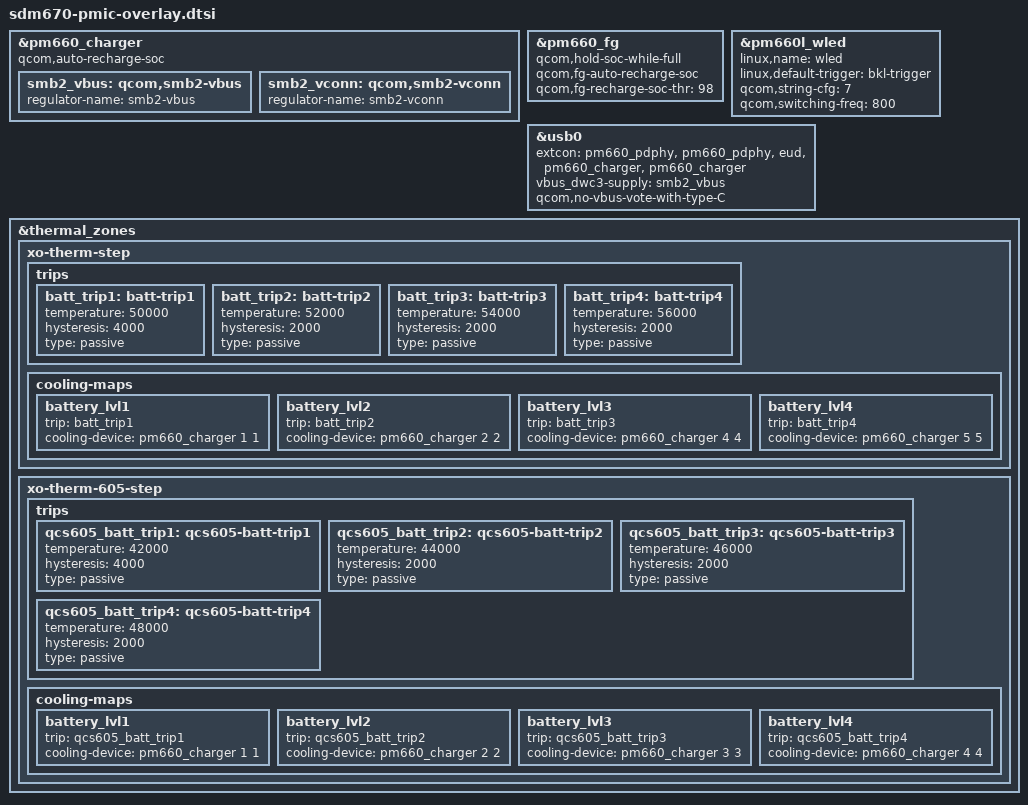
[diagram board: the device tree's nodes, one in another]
/* Copyright (c) 2017-2019, The Linux Foundation. All rights reserved.
 *
 * This program is free software; you can redistribute it and/or modify
 * it under the terms of the GNU General Public License version 2 and
 * only version 2 as published by the Free Software Foundation.
 *
 * This program is distributed in the hope that it will be useful,
 * but WITHOUT ANY WARRANTY; without even the implied warranty of
 * MERCHANTABILITY or FITNESS FOR A PARTICULAR PURPOSE.  See the
 * GNU General Public License for more details.
 */

#include <dt-bindings/interrupt-controller/arm-gic.h>

&pm660_charger {
	#cooling-cells = <2>;
	qcom,auto-recharge-soc;

	smb2_vbus: qcom,smb2-vbus {
		regulator-name = "smb2-vbus";
	};

	smb2_vconn: qcom,smb2-vconn {
		regulator-name = "smb2-vconn";
	};
};

&pm660_fg {
	qcom,hold-soc-while-full;
	qcom,fg-auto-recharge-soc;
	qcom,fg-recharge-soc-thr = <98>;
};

&pm660l_wled {
	linux,name = "wled";
	linux,default-trigger = "bkl-trigger";
	qcom,string-cfg = <7>;
	qcom,switching-freq = <800>;
};

&usb0 {
	extcon = <&pm660_pdphy>, <&pm660_pdphy>, <&eud>,
					<&pm660_charger>, <&pm660_charger>;
	vbus_dwc3-supply = <&smb2_vbus>;
	qcom,no-vbus-vote-with-type-C;
};

&thermal_zones {
	xo-therm-step {
		trips {
			batt_trip1: batt-trip1 {
				temperature = <50000>;
				hysteresis = <4000>;
				type = "passive";
			};
			batt_trip2: batt-trip2 {
				temperature = <52000>;
				hysteresis = <2000>;
				type = "passive";
			};
			batt_trip3: batt-trip3 {
				temperature = <54000>;
				hysteresis = <2000>;
				type = "passive";
			};
			batt_trip4: batt-trip4 {
				temperature = <56000>;
				hysteresis = <2000>;
				type = "passive";
			};
		};

		cooling-maps {
			battery_lvl1 {
				trip = <&batt_trip1>;
				cooling-device = <&pm660_charger 1 1>;
			};
			battery_lvl2 {
				trip = <&batt_trip2>;
				cooling-device = <&pm660_charger 2 2>;
			};
			battery_lvl3 {
				trip = <&batt_trip3>;
				cooling-device = <&pm660_charger 4 4>;
			};
			battery_lvl4 {
				trip = <&batt_trip4>;
				cooling-device = <&pm660_charger 5 5>;
			};
		};
	};

	xo-therm-605-step {
		trips {
			qcs605_batt_trip1: qcs605-batt-trip1 {
				temperature = <42000>;
				hysteresis = <4000>;
				type = "passive";
			};
			qcs605_batt_trip2: qcs605-batt-trip2 {
				temperature = <44000>;
				hysteresis = <2000>;
				type = "passive";
			};
			qcs605_batt_trip3: qcs605-batt-trip3 {
				temperature = <46000>;
				hysteresis = <2000>;
				type = "passive";
			};
			qcs605_batt_trip4: qcs605-batt-trip4 {
				temperature = <48000>;
				hysteresis = <2000>;
				type = "passive";
			};
		};
		cooling-maps {
			battery_lvl1 {
				trip = <&qcs605_batt_trip1>;
				cooling-device = <&pm660_charger 1 1>;
			};
			battery_lvl2 {
				trip = <&qcs605_batt_trip2>;
				cooling-device = <&pm660_charger 2 2>;
			};
			battery_lvl3 {
				trip = <&qcs605_batt_trip3>;
				cooling-device = <&pm660_charger 3 3>;
			};
			battery_lvl4 {
				trip = <&qcs605_batt_trip4>;
				cooling-device = <&pm660_charger 4 4>;
			};
		};
	};
};
